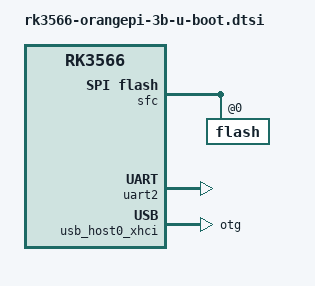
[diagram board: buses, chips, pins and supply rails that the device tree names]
// SPDX-License-Identifier: GPL-2.0+

#include "rk356x-u-boot.dtsi"

&gpio4 {
	bootph-pre-ram;
};

&sfc {
	flash@0 {
		bootph-pre-ram;
		bootph-some-ram;
	};
};

&vdd_npu {
	regulator-always-on;
	regulator-boot-on;
	regulator-init-microvolt = <900000>;
};

&uart2 {
	clock-frequency = <24000000>;
	bootph-all;
	status = "okay";
};

&usb_host0_ohci {
	status = "disable";
};

&usb_host0_xhci {
	dr_mode = "otg";
	status = "okay";
};
